AUTOSAR XML (schema 4-3-0)
package /Swc
  application sw component type SpeedSensor
    provide port VehicleSpeed: provided-interface=VehicleSpeed_If
  application sw component type EngineMonitor
    provide port EngineSpeed: provided-interface=EngineSpeed_If
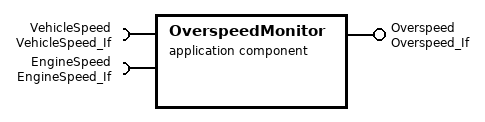
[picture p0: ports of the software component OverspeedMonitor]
  application sw component type OverspeedMonitor
    require port VehicleSpeed: required-interface=VehicleSpeed_If
    require port EngineSpeed: required-interface=EngineSpeed_If
    provide port Overspeed: provided-interface=Overspeed_If
  application sw component type Cluster
    require port Overspeed: required-interface=Overspeed_If
